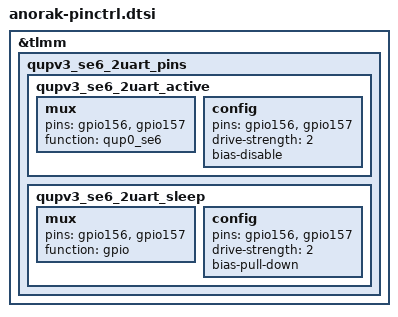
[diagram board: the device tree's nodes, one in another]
&tlmm {
	qupv3_se6_2uart_pins: qupv3_se6_2uart_pins {
		qupv3_se6_2uart_active: qupv3_se6_2uart_active {
			mux {
				pins = "gpio156", "gpio157";
				function = "qup0_se6";
			};

			config {
				pins = "gpio156", "gpio157";
				drive-strength= <2>;
				bias-disable;
			};
		};

		qupv3_se6_2uart_sleep: qupv3_se6_2uart_sleep {
			mux {
				pins = "gpio156", "gpio157";
				function = "gpio";
			};

			config {
				pins = "gpio156", "gpio157";
				drive-strength = <2>;
				bias-pull-down;
			};
		};
	};
};
